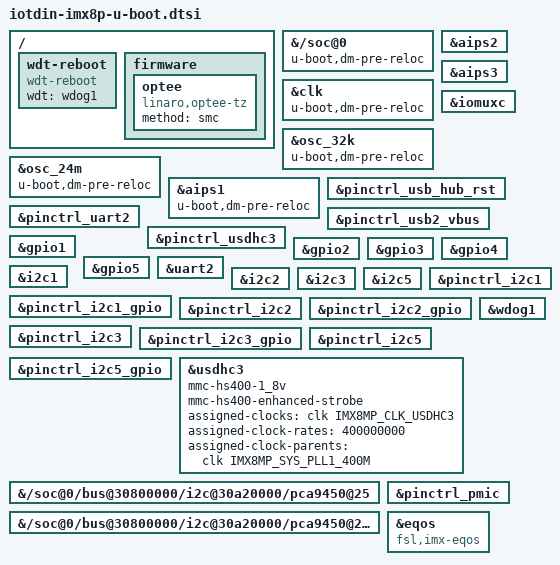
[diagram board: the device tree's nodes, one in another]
// SPDX-License-Identifier: GPL-2.0+
/*
 * Copyright 2019 NXP
 * Copyright 2024 CompuLab
 */

/ {
	wdt-reboot {
		compatible = "wdt-reboot";
		wdt = <&wdog1>;
		u-boot,dm-spl;
	};

	firmware {
		optee {
			compatible = "linaro,optee-tz";
			method = "smc";
		};
	};
};

&{/soc@0} {
	u-boot,dm-pre-reloc;
	u-boot,dm-spl;
};

&clk {
	u-boot,dm-spl;
	u-boot,dm-pre-reloc;
	/delete-property/ assigned-clocks;
	/delete-property/ assigned-clock-parents;
	/delete-property/ assigned-clock-rates;

};

&osc_32k {
	u-boot,dm-spl;
	u-boot,dm-pre-reloc;
};

&osc_24m {
	u-boot,dm-spl;
	u-boot,dm-pre-reloc;
};

&aips1 {
	u-boot,dm-spl;
	u-boot,dm-pre-reloc;
};

&aips2 {
	u-boot,dm-spl;
};

&aips3 {
	u-boot,dm-spl;
};

&iomuxc {
	u-boot,dm-spl;
};

&pinctrl_usb_hub_rst {
	u-boot,dm-spl;
};

&pinctrl_usb2_vbus {
	u-boot,dm-spl;
};

&pinctrl_uart2 {
	u-boot,dm-spl;
};

&pinctrl_usdhc3 {
	u-boot,dm-spl;
};

&gpio1 {
	u-boot,dm-spl;
};

&gpio2 {
	u-boot,dm-spl;
};

&gpio3 {
	u-boot,dm-spl;
};

&gpio4 {
	u-boot,dm-spl;
};

&gpio5 {
	u-boot,dm-spl;
};

&uart2 {
	u-boot,dm-spl;
};

&i2c1 {
	u-boot,dm-spl;
};

&i2c2 {
	u-boot,dm-spl;
};

&i2c3 {
	u-boot,dm-spl;
};

&i2c5 {
	u-boot,dm-spl;
};

&pinctrl_i2c1 {
	u-boot,dm-spl;
};

&pinctrl_i2c1_gpio {
	u-boot,dm-spl;
};

&pinctrl_i2c2 {
	u-boot,dm-spl;
};

&pinctrl_i2c2_gpio {
	u-boot,dm-spl;
};

&pinctrl_i2c3 {
	u-boot,dm-spl;
};

&pinctrl_i2c3_gpio {
	u-boot,dm-spl;
};

&pinctrl_i2c5 {
	u-boot,dm-spl;
};

&pinctrl_i2c5_gpio {
	u-boot,dm-spl;
};

&usdhc3 {
	u-boot,dm-spl;
	mmc-hs400-1_8v;
	mmc-hs400-enhanced-strobe;
	assigned-clocks = <&clk IMX8MP_CLK_USDHC3>;
	assigned-clock-rates = <400000000>;
	assigned-clock-parents = <&clk IMX8MP_SYS_PLL1_400M>;
};

&wdog1 {
	u-boot,dm-spl;
};

&{/soc@0/bus@30800000/i2c@30a20000/pca9450@25} {
	u-boot,dm-spl;
};

&{/soc@0/bus@30800000/i2c@30a20000/pca9450@25/regulators} {
	u-boot,dm-spl;
};

&pinctrl_pmic {
	u-boot,dm-spl;
};

&eqos {
	compatible = "fsl,imx-eqos";
	/delete-property/ assigned-clocks;
	/delete-property/ assigned-clock-parents;
	/delete-property/ assigned-clock-rates;
};
